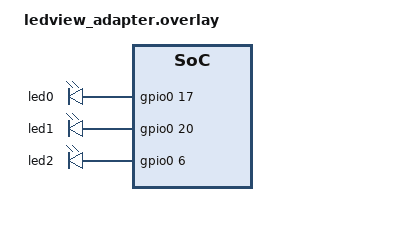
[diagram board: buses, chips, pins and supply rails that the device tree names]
/ {
    aliases {
        led-red = &led0;
        led-green = &led1;
        led-blue = &led2;
    };

    leds {
        compatible = "gpio-leds";
        status = "okay";
        led0: led_0 {
            gpios = <&gpio0 17 GPIO_ACTIVE_HIGH>;  // red LED, connected to P0.17
        };
        led1: led_1 {
            gpios = <&gpio0 20 GPIO_ACTIVE_HIGH>;  // green LED, connected to P0.20
        };
        led2: led_2 {
            gpios = <&gpio0 6 GPIO_ACTIVE_HIGH>;  // blue LED, connected to P0.06
        };
    };
};
